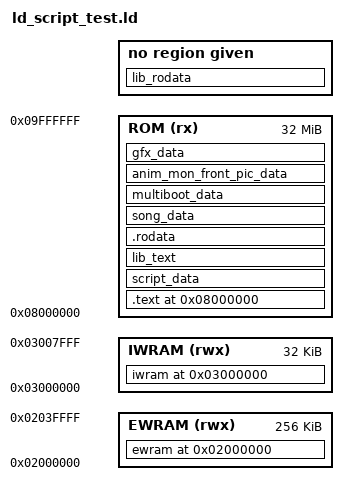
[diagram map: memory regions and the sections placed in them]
/*
 * ld_script_test.ld
 *
 * Linker script for the test ROM produced by `make test`. Identical to
 * ld_script_modern.ld in section layout; the only material difference
 * is that gInitialMainCB2 resolves to CB2_TestRunner instead of the
 * normal title-screen path. This causes the test ROM to skip directly
 * into the test harness on boot.
 *
 * The test/ object directory is included in the .text and bss sections
 * so the harness's compilation units link in alongside the rest of the
 * engine code.
 */

ENTRY(Start)

gNumMusicPlayers = 4;
gMaxLines = 0;
gInitialMainCB2 = CB2_TestRunner;

MEMORY
{
    EWRAM (rwx) : ORIGIN = 0x2000000, LENGTH = 256K
    IWRAM (rwx) : ORIGIN = 0x3000000, LENGTH = 32K
    ROM    (rx) : ORIGIN = 0x8000000, LENGTH = 32M
}

SECTIONS {

    ewram 0x2000000 (NOLOAD) :
    ALIGN(4)
    {
        src/*.o(ewram_data);
        test/*.o(ewram_data);
    } > EWRAM

    iwram 0x3000000 (NOLOAD) :
    ALIGN(4)
    {
        src/*.o(.bss);
        data/*.o(.bss);
        test/*.o(.bss);
        *libc.a:*.o(.bss*);
        *libnosys.a:*.o(.bss*);

        src/m4a.o(.bss.code);

        src/*.o(common_data);
        src/*.o(COMMON);
        test/*.o(COMMON);
        *libc.a:*.o(COMMON);
        *libnosys.a:*.o(COMMON);
    } > IWRAM

    /* BEGIN ROM DATA */
    . = 0x8000000;

    .text :
    ALIGN(4)
    {
        src/rom_header.o(.text*);
        src/rom_header_gf.o(.text.*);
        src/crt0.o(.text);
        src/main.o(.text);
        src/*.o(.text*);
        asm/*.o(.text*);
        test/*.o(.text*);
    } > ROM =0

    script_data :
    ALIGN(4)
    {
		data/*.o(script_data);
    } > ROM =0

    lib_text :
    ALIGN(4)
    {
        src/libgcnmultiboot.o(.text);
        src/m4a_1.o(.text);
        src/m4a.o(.text);
        src/agb_flash.o(.text);
        src/agb_flash_1m.o(.text);
        src/agb_flash_mx.o(.text);
        src/siirtc.o(.text);
        src/librfu_stwi.o(.text);
        src/librfu_intr.o(.text);
        src/librfu_rfu.o(.text);
        src/librfu_sio32id.o(.text);
        *libagbsyscall.a:*.o(.text*);
        *libgcc.a:*.o(.text*);
        *libc.a:*.o(.text*);
        *libnosys.a:*.o(.text*);
        src/libisagbprn.o(.text);
    } > ROM =0

    .rodata :
    ALIGN(4)
    {
        src/*.o(.rodata*);
        data/*.o(.rodata*);
        test/*.o(.rodata*);
    } > ROM =0

    song_data :
    ALIGN(4)
    {
        sound/songs/*.o(.rodata);
    } > ROM =0

    lib_rodata :
    SUBALIGN(4)
    {
        src/m4a.o(.rodata);
        src/agb_flash.o(.rodata);
        src/agb_flash_1m.o(.rodata);
        src/agb_flash_mx.o(.rodata);
        src/agb_flash_le.o(.rodata);
        src/siirtc.o(.rodata);
        src/librfu_rfu.o(.rodata);
        src/librfu_sio32id.o(.rodata);
        *libgcc.a:*.o(.rodata*);
        *libc.a:*.o(.rodata*);
        *libc.a:*.o(.data*);
        src/libisagbprn.o(.rodata);
    } =0

    multiboot_data :
    ALIGN(4)
    {
        data/multiboot_ereader.o(.rodata);
        data/multiboot_berry_glitch_fix.o(.rodata);
        data/multiboot_pokemon_colosseum.o(.rodata);
    } > ROM =0

    anim_mon_front_pic_data :
    ALIGN(4)
    {
        src/anim_mon_front_pics.o(.rodata);
    } > ROM =0

    gfx_data :
    ALIGN(4)
    {
        src/graphics.o(.rodata);
    } > ROM =0

    /* DWARF debug sections. */
    .debug          0 : { *(.debug) }
    .line           0 : { *(.line) }
    .debug_srcinfo  0 : { *(.debug_srcinfo) }
    .debug_sfnames  0 : { *(.debug_sfnames) }
    .debug_aranges  0 : { *(.debug_aranges) }
    .debug_pubnames 0 : { *(.debug_pubnames) }
    .debug_info     0 : { *(.debug_info .gnu.linkonce.wi.*) }
    .debug_abbrev   0 : { *(.debug_abbrev) }
    .debug_line     0 : { *(.debug_line) }
    .debug_frame    0 : { *(.debug_frame) }
    .debug_str      0 : { *(.debug_str) }
    .debug_loc      0 : { *(.debug_loc) }
    .debug_macinfo  0 : { *(.debug_macinfo) }
    .debug_line_str     0 : { *(.debug_line_str) }

    /DISCARD/ :
    {
        *(*);
    }
}
